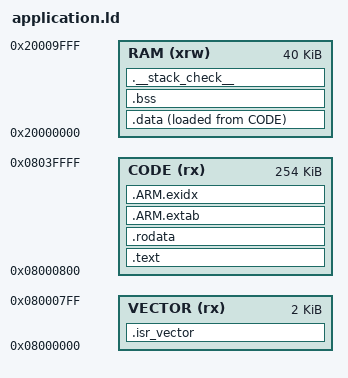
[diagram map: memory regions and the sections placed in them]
/**
 * -------------------------------------------------------------------------------------------------
 * @author  Ryan Sullivan (ryansullivan@googlemail.com)
 *
 * @file    application.ld
 * @brief   Linker command script for linking the application.
 *
 * @date    2022-02-15
 * -------------------------------------------------------------------------------------------------
 */

/* Section Declarations. */
MEMORY
{
    VECTOR (rx) : ORIGIN = 0x08000000, LENGTH = 2K
    CODE (rx)   : ORIGIN = 0x08000800, LENGTH = 254K
    RAM (xrw)   : ORIGIN = 0x20000000, LENGTH = 40K
}

/*
 * Define the stack location and limits.
 */
__stack__ = ORIGIN(RAM) + LENGTH(RAM);
__max_stack_size__ = 1024;
__min_stack_size__ = 256;

SECTIONS
{
    /*
     * Vector table.
     */
    .isr_vector : ALIGN(4)
    {     
        __vectors_start__ = .;
        __code_start__ = .;
        KEEP(*(.isr_vector))

        . = ALIGN(0x800);
        __vectors_end__ = .;

    } >VECTOR =0xFF

    /*
     * Code.
     */
    .text : ALIGN(4)
    {
        FILL(0xFF)

        __text_start__ = .;
        *(.text .text.*)
        		
		/*
		 * Stub sections generated by the linker, to glue together 
		 * ARM and Thumb code. .glue_7 is used for ARM code calling 
		 * Thumb code, and .glue_7t is used for Thumb code calling 
		 * ARM code. Apparently always generated by the linker, for some
		 * architectures, so better leave them here.
		 */
        *(.glue_7)
        *(.glue_7t)

        . = ALIGN(4);
        __text_end__ = .;
    } >CODE

    /*
     * Read only data.
     */
    .rodata : ALIGN(4)
    {
        FILL(0xFF)

        __rodata_start__ = .;
        *(.rodata .rodata.* .constdata .constdata.*) 

        . = ALIGN(4);
        __rodata_end__ = .;
    } >CODE

    /*
     * Code area and symbols used by default C++ libraries. 
     */
	.ARM.extab : ALIGN(4)
   	{
       *(.ARM.extab* .gnu.linkonce.armextab.*)
       
       . = ALIGN(4);
   	} > CODE
   	
   	.ARM.exidx : ALIGN(4)
   	{
        __exidx_start = .;
       *(.ARM.exidx* .gnu.linkonce.armexidx.*)

       . = ALIGN(4);
       __exidx_end = .;
       __code_end__ = .;
   	} > CODE
   	
   	
    

    /*
     * Initialised data.
     */
    .data : ALIGN(4)
    {
    	FILL(0xFF)

        __data_start__ = .;
		*(.data .data.*)

	    . = ALIGN(4);
        __data_end__ = .;
    } >RAM AT>CODE
    __data_len__ = SIZEOF(.data);
    
    /*
     * Uninitialised data.
     */
    .bss (NOLOAD) : ALIGN(4)
    {
        FILL(0xFF)
        
        __bss_start__ = .;
        *(.bss .bss.*)
        *(COMMON)
        
	    . = ALIGN(4);
        __bss_end__ = .;
    } >RAM
    __bss_len__ = SIZEOF(.bss);
    
    /*
     * Check that thaere's enough room in RAM for the stack.
     */
    .__stack_check__ : ALIGN(4)
    {
        ASSERT(__stack__ > (. + __min_stack_size__), "Error: No room left for the stack");
    } >RAM    

    /* 
     * Stabs debugging sections.
     */
    .stab          0 : { *(.stab) }
    .stabstr       0 : { *(.stabstr) }
    .stab.excl     0 : { *(.stab.excl) }
    .stab.exclstr  0 : { *(.stab.exclstr) }
    .stab.index    0 : { *(.stab.index) }
    .stab.indexstr 0 : { *(.stab.indexstr) }
    .comment       0 : { *(.comment) }
    
    /*
     * DWARF debug sections.
     * Symbols in the DWARF debugging sections are relative to the beginning
     * of the section so we begin them at 0.  
     */
    /* DWARF 1 */
    .debug          0 : { *(.debug) }
    .line           0 : { *(.line) }
    /* GNU DWARF 1 extensions */
    .debug_srcinfo  0 : { *(.debug_srcinfo) }
    .debug_sfnames  0 : { *(.debug_sfnames) }
    /* DWARF 1.1 and DWARF 2 */
    .debug_aranges  0 : { *(.debug_aranges) }
    .debug_pubnames 0 : { *(.debug_pubnames) }
    /* DWARF 2 */
    .debug_info     0 : { *(.debug_info .gnu.linkonce.wi.*) }
    .debug_abbrev   0 : { *(.debug_abbrev) }
    .debug_line     0 : { *(.debug_line) }
    .debug_frame    0 : { *(.debug_frame) }
    .debug_str      0 : { *(.debug_str) }
    .debug_loc      0 : { *(.debug_loc) }
    .debug_macinfo  0 : { *(.debug_macinfo) }
    /* SGI/MIPS DWARF 2 extensions */
    .debug_weaknames 0 : { *(.debug_weaknames) }
    .debug_funcnames 0 : { *(.debug_funcnames) }
    .debug_typenames 0 : { *(.debug_typenames) }
    .debug_varnames  0 : { *(.debug_varnames) }    
}
